# R7FA4E10D register map
Vendor: Renesas Electronics Corporation; Series: RA4E1; File version: 1.20.00
CPU: CM33 r0p4, little endian, MPU, FPU, VTOR, 4 interrupt priority bits, 96 interrupts
Registers are 8-bit, read-write, reset 0x0 unless marked. A register's access mark holds for its fields unless they carry their own. Offsets are from the block's base; [hi:lo] are bit positions; {n}, {i} and the like mark numbered series.

## RMPU — Renesas Memory Protection Unit
Base 0x40000000
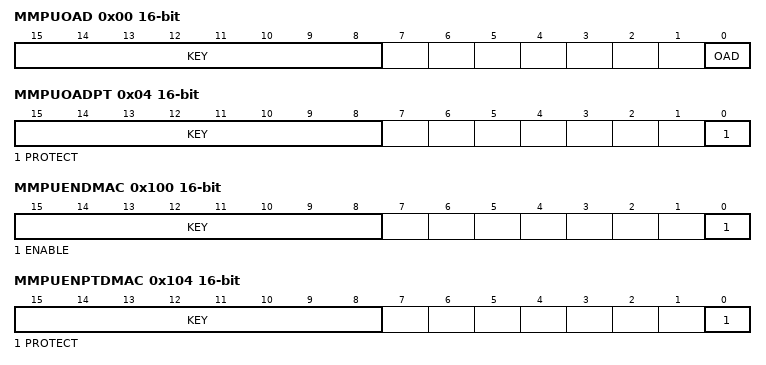
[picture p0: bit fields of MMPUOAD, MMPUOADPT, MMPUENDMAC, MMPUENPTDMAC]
0x00 MMPUOAD 16-bit — MMPU Operation After Detection Register
  [15:8] KEY wo — This bit enables or disables writes to the OAD bit.
  [0] OAD — Operation after detection
    0=Non-maskable interrupt; 1=Reset
0x04 MMPUOADPT 16-bit — MMPU Operation After Detection Protect Register
  [15:8] KEY wo — Key code
  [0] PROTECT — Protection of register
    0=MMPUOAD register writes are possible; 1=MMPUOAD register writes are protected. Read is possible.
0x100 MMPUENDMAC 16-bit — MMPU Enable Register for DMAC
  [15:8] KEY wo — These bits enable or disable writes to the ENABLE bit.
  [0] ENABLE — Bus Master MPU of DMAC enable
    0=Bus Master MPU of DMAC is disabled; 1=Bus Master MPU of DMAC is enabled
0x104 MMPUENPTDMAC 16-bit — MMPU Enable Protect Register for DMAC
  [15:8] KEY wo — These bits enable or disable writes to the PROTECT bit.
  [0] PROTECT — Protection of register
    0=MMPUENDMAC register writes are possible; 1=MMPUENDMAC register writes are protected. Read is possible.
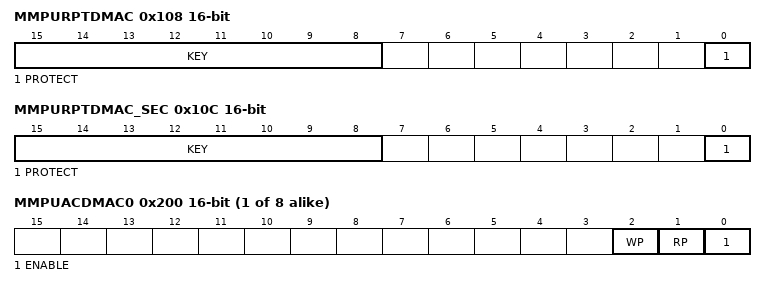
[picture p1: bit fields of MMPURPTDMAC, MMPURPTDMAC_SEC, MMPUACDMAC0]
0x108 MMPURPTDMAC 16-bit — MMPU Regions Protect Register for DMAC
  [15:8] KEY wo — These bits enable or disable writes to the PROTECT bit.
  [0] PROTECT — Protection of register
    0=Bus Master MPU register for DMAC writing is possible; 1=Bus Master MPU register for DMAC writing is protected. Read is possible.
0x10C MMPURPTDMAC_SEC 16-bit — MMPU Regions Protect register for DMAC Secure
  [15:8] KEY wo — These bits enable or disable writes to the PROTECT bit.
  [0] PROTECT — Protection of register
    0=Bus master MPU register for DMAC secure writes are possible; 1=Bus master MPU register for DMAC secure writes are protected. Read is possible.
{0x200+0x10*i} MMPUACDMAC{i} (i=0..7) 16-bit — MMPU Access Control Register for DMAC
  [2] WP — Write protection
    0=Write permission; 1=Write protection
  [1] RP — Read protection
    0=Read permission; 1=Read protection
  [0] ENABLE — Region enable
    0=DMAC Region n unit is disabled; 1=DMAC Region n unit is enabled
{0x204+0x10*i} MMPUSDMAC{i} (i=0..7) 32-bit (reset mask 0x1F) — MMPU Start Address Register for DMAC
  [31:5] MMPUS — Region start address register
{0x208+0x10*i} MMPUEDMAC{i} (i=0..7) 32-bit reset 0x1F (reset mask 0x1F) — MMPU End Address Register for DMAC
  [31:5] MMPUE — Region end address register

## TZF — TrustZone Filter
Base 0x40000E00
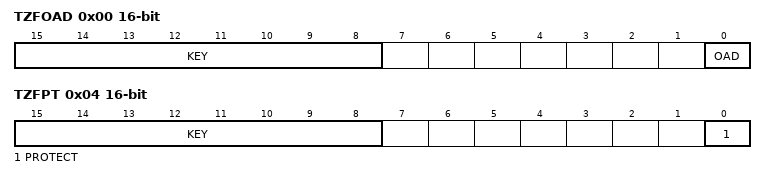
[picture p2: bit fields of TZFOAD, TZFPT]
0x00 TZFOAD 16-bit — TrustZone Filter Operation After Detection Register
  [15:8] KEY wo — KeyCode
  [0] OAD — Operation after detection
    0=Non-maskable interrupt; 1=Reset
0x04 TZFPT 16-bit — TrustZone Filter Protect Register
  [15:8] KEY wo — KeyCode
  [0] PROTECT — Protection of register
    0=All Bus TrustZone Filter register writing is protected. Read is possible.; 1=All Bus TrustZone Filter register writing is possible

## SRAM — SRAM Control
Base 0x40002000
0x00 PARIOAD — SRAM Parity Error Operation After Detection Register
  [0] OAD — Operation After Detection
    0=Non-maskable interrupt; 1=Reset
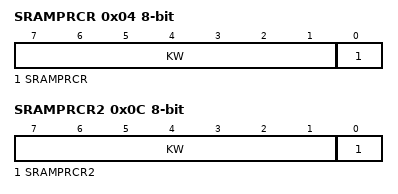
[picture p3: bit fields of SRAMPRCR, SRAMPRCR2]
0x04 SRAMPRCR — SRAM Protection Register
  [7:1] KW wo — Write Key Code
  [0] SRAMPRCR — Register Write Control
    0=Disable writes to protected registers; 1=Enable writes to protected registers
0x08 SRAMWTSC reset 0x1 — SRAM Wait State Control Register
  [0] SRAM0WTEN — SRAM0 wait enable
    0=No wait; 1=Add wait state in read access cycle to SRAM0
0x0C SRAMPRCR2 — SRAM Protection Register 2
  [7:1] KW wo — Write Key Code
  [0] SRAMPRCR2 — Register Write Control
    0=Disable writes to the protected registers; 1=Enable writes to the protected registers

## Notices in the file
This software is supplied by Renesas Electronics Corporation and is only intended for
use with Renesas products. No other uses are authorized. This software is owned by
Renesas Electronics Corporation and is protected under all applicable laws, including
copyright laws.
THIS SOFTWARE IS PROVIDED "AS IS" AND RENESAS MAKES NO WARRANTIES REGARDING
THIS SOFTWARE, WHETHER EXPRESS, IMPLIED OR STATUTORY, INCLUDING BUT NOT LIMITED TO
WARRANTIES OF MERCHANTABILITY, FITNESS FOR A PARTICULAR PURPOSE AND NON-INFRINGEMENT.
ALL SUCH WARRANTIES ARE EXPRESSLY DISCLAIMED. TO THE MAXIMUM EXTENT PERMITTED NOT
PROHIBITED BY LAW, NEITHER RENESAS ELECTRONICS CORPORATION NOR ANY OF ITS AFFILIATED
COMPANIES SHALL BE LIABLE FOR ANY DIRECT, INDIRECT, SPECIAL, INCIDENTAL OR CONSEQUENTIAL
DAMAGES FOR ANY REASON RELATED TO THIS SOFTWARE, EVEN IF RENESAS OR ITS AFFILIATES HAVE
BEEN ADVISED OF THE POSSIBILITY OF SUCH DAMAGES.
Renesas reserves the right, without notice, to make changes to this software and to
discontinue the availability of this software. By using this software, you agree to
the additional terms and conditions found by accessing the following link:
http://www.renesas.com/disclaimer
